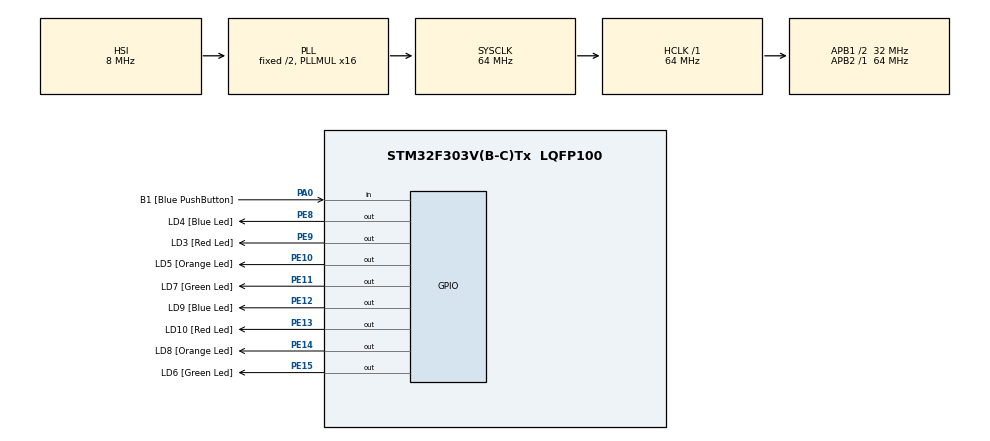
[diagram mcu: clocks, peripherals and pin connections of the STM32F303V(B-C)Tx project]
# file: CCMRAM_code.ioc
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Mcu.Family=STM32F3
Mcu.Name=STM32F303V(B-C)Tx
Mcu.Package=LQFP100
NVIC.PriorityGroup=NVIC_PRIORITYGROUP_0
NVIC.RCC_IRQn=true\:0\:0\:false\:false\:true\:true\:false\:true
NVIC.TIM7_IRQn=true\:0\:0\:false\:false\:true\:true\:true\:true
PA0.GPIO_Label=B1 [Blue PushButton]
PA0.Signal=GPIO_Input
PA13.GPIO_Label=SWDIO
PA13.Mode=Trace_Asynchronous_SW
PA13.Signal=SYS_JTMS-SWDIO
PA14.GPIO_Label=SWCLK
PA14.Mode=Trace_Asynchronous_SW
PA14.Signal=SYS_JTCK-SWCLK
PB3.GPIO_Label=SWO
PB3.Mode=Trace_Asynchronous_SW
PB3.Signal=SYS_JTDO-TRACESWO
PE10.GPIO_Label=LD5 [Orange Led]
PE10.Signal=GPIO_Output
PE11.GPIO_Label=LD7 [Green Led]
PE11.Signal=GPIO_Output
PE12.GPIO_Label=LD9 [Blue Led]
PE12.Signal=GPIO_Output
PE13.GPIO_Label=LD10 [Red Led]
PE13.Signal=GPIO_Output
PE14.GPIO_Label=LD8 [Orange Led]
PE14.Signal=GPIO_Output
PE15.GPIO_Label=LD6 [Green Led]
PE15.Signal=GPIO_Output
PE8.GPIO_Label=LD4 [Blue Led]
PE8.Signal=GPIO_Output
PE9.GPIO_Label=LD3 [Red Led]
PE9.Signal=GPIO_Output
ProjectManager.HeapSize=0x200
ProjectManager.StackSize=0x400
ProjectManager.TargetToolchain=STM32CubeIDE
RCC.AHBFreq_Value=64000000
RCC.APB1CLKDivider=RCC_HCLK_DIV2
RCC.APB1Freq_Value=32000000
RCC.APB1TimFreq_Value=64000000
RCC.APB2Freq_Value=64000000
RCC.APB2TimFreq_Value=64000000
RCC.CortexFreq_Value=64000000
RCC.HCLKFreq_Value=64000000
RCC.HSE_VALUE=8000000
RCC.HSI_VALUE=8000000
RCC.PLLMUL=RCC_PLL_MUL16
RCC.SYSCLKFreq_VALUE=64000000
RCC.SYSCLKSourceVirtual=RCC_SYSCLKSOURCE_PLLCLK
RCC.USBFreq_Value=64000000
TIM7.AutoReloadPreload=TIM_AUTORELOAD_PRELOAD_ENABLE
TIM7.Period=1000-1
TIM7.Prescaler=64000-1
VP_TIM7_VS_ClockSourceINT.Mode=Enable_Timer
board=STM32F3DISCOVERY

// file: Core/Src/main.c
/* USER CODE BEGIN Header */
/**
  ******************************************************************************
  * @file           : main.c
  * @brief          : Main program body
  ******************************************************************************
  * @attention
  *
  * Copyright (c) 2024 STMicroelectronics.
  * All rights reserved.
  *
  * This software is licensed under terms that can be found in the LICENSE file
  * in the root directory of this software component.
  * If no LICENSE file comes with this software, it is provided AS-IS.
  *
  ******************************************************************************
  */
/* USER CODE END Header */
#include "main.h"
#include "tim.h"
#include "gpio.h"

/* USER CODE BEGIN Includes */

#include "main_fw.h"

/* USER CODE END Includes */

void SystemClock_Config(void);

int main(void)
{

  /* MCU Configuration--------------------------------------------------------*/

  /* Reset of all peripherals, Initializes the Flash interface and the Systick. */
  HAL_Init();

  /* Configure the system clock */
  SystemClock_Config();

  /* Initialize all configured peripherals */
  MX_GPIO_Init();
  MX_TIM7_Init();

  /* Infinite loop */
  /* USER CODE BEGIN WHILE */
  while (1)
  {
	  main_fw();
    /* USER CODE END WHILE */

  }
}

void SystemClock_Config(void)
{
  RCC_OscInitTypeDef RCC_OscInitStruct = {0};
  RCC_ClkInitTypeDef RCC_ClkInitStruct = {0};

  /** Initializes the RCC Oscillators according to the specified parameters
  * in the RCC_OscInitTypeDef structure.
  */
  RCC_OscInitStruct.OscillatorType = RCC_OSCILLATORTYPE_HSI;
  RCC_OscInitStruct.HSIState = RCC_HSI_ON;
  RCC_OscInitStruct.HSICalibrationValue = RCC_HSICALIBRATION_DEFAULT;
  RCC_OscInitStruct.PLL.PLLState = RCC_PLL_ON;
  RCC_OscInitStruct.PLL.PLLSource = RCC_PLLSOURCE_HSI;
  RCC_OscInitStruct.PLL.PLLMUL = RCC_PLL_MUL16;
  if (HAL_RCC_OscConfig(&RCC_OscInitStruct) != HAL_OK)
  {
    Error_Handler();
  }

  /** Initializes the CPU, AHB and APB buses clocks
  */
  RCC_ClkInitStruct.ClockType = RCC_CLOCKTYPE_HCLK|RCC_CLOCKTYPE_SYSCLK
                              |RCC_CLOCKTYPE_PCLK1|RCC_CLOCKTYPE_PCLK2;
  RCC_ClkInitStruct.SYSCLKSource = RCC_SYSCLKSOURCE_PLLCLK;
  RCC_ClkInitStruct.AHBCLKDivider = RCC_SYSCLK_DIV1;
  RCC_ClkInitStruct.APB1CLKDivider = RCC_HCLK_DIV2;
  RCC_ClkInitStruct.APB2CLKDivider = RCC_HCLK_DIV1;

  if (HAL_RCC_ClockConfig(&RCC_ClkInitStruct, FLASH_LATENCY_2) != HAL_OK)
  {
    Error_Handler();
  }
}

void Error_Handler(void)
{
  __disable_irq();
  while (1)
  {
  }
}
